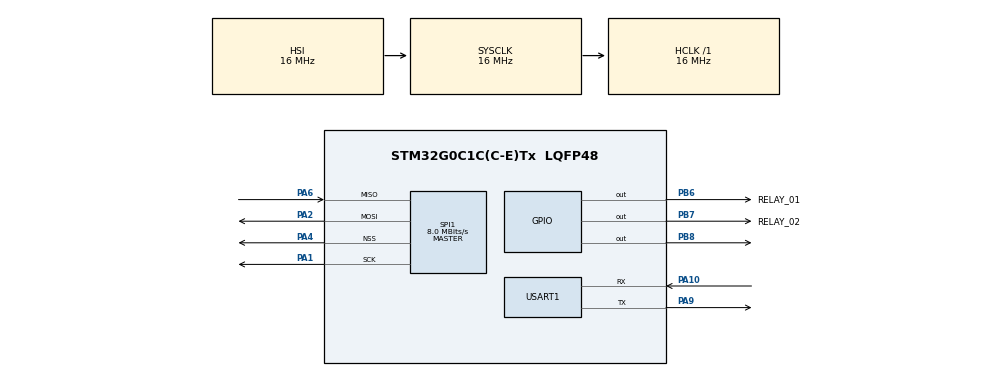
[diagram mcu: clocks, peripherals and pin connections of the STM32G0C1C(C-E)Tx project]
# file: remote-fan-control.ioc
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Mcu.Family=STM32G0
Mcu.Name=STM32G0C1C(C-E)Tx
Mcu.Package=LQFP48
PA1.Mode=Full_Duplex_Master
PA1.Signal=SPI1_SCK
PA10.Mode=Asynchronous
PA10.Signal=USART1_RX
PA2.Mode=Full_Duplex_Master
PA2.Signal=SPI1_MOSI
PA4.Mode=NSS_Signal_Hard_Output
PA4.Signal=SPI1_NSS
PA6.Mode=Full_Duplex_Master
PA6.Signal=SPI1_MISO
PA9.Mode=Asynchronous
PA9.Signal=USART1_TX
PB6.GPIO_Label=RELAY_01
PB6.Signal=GPIO_Output
PB7.GPIO_Label=RELAY_02
PB7.Signal=GPIO_Output
PB8.Signal=GPIO_Output
ProjectManager.HeapSize=0x200
ProjectManager.StackSize=0x400
ProjectManager.TargetToolchain=STM32CubeIDE
RCC.AHBFreq_Value=16000000
RCC.CortexFreq_Value=16000000
RCC.EXTERNAL_CLOCK_VALUE=48000
RCC.HCLKFreq_Value=16000000
RCC.HSE_VALUE=8000000
RCC.HSI48_VALUE=48000000
RCC.HSI_VALUE=16000000
RCC.LSE_VALUE=32768
RCC.SYSCLKFreq_VALUE=16000000
RCC.USBFreq_Value=48000000
RCC.VCOOutputFreq_Value=128000000
SPI1.CalculateBaudRate=8.0 MBits/s
SPI1.Direction=SPI_DIRECTION_2LINES
SPI1.Mode=SPI_MODE_MASTER
SPI1.VirtualNSS=VM_NSSHARD
SPI1.VirtualType=VM_MASTER
USART1.VirtualMode-Asynchronous=VM_ASYNC
VP_SYS_VS_DBSignals.Mode=DisableDeadBatterySignals
board=custom

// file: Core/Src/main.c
/* USER CODE BEGIN Header */
/**
  ******************************************************************************
  * @file           : main.c
  * @brief          : Main program body
  ******************************************************************************
  * @attention
  *
  * Copyright (c) 2026 STMicroelectronics.
  * All rights reserved.
  *
  * This software is licensed under terms that can be found in the LICENSE file
  * in the root directory of this software component.
  * If no LICENSE file comes with this software, it is provided AS-IS.
  *
  ******************************************************************************
  */
/* USER CODE END Header */
#include "main.h"

SPI_HandleTypeDef hspi1;

UART_HandleTypeDef huart1;

void SystemClock_Config(void);
static void MX_GPIO_Init(void);
static void MX_SPI1_Init(void);
static void MX_USART1_UART_Init(void);

int main(void)
{

  /* MCU Configuration--------------------------------------------------------*/

  /* Reset of all peripherals, Initializes the Flash interface and the Systick. */
  HAL_Init();

  /* Configure the system clock */
  SystemClock_Config();

  /* Initialize all configured peripherals */
  MX_GPIO_Init();
  MX_SPI1_Init();
  MX_USART1_UART_Init();
  /* USER CODE BEGIN 2 */
  char cmd[128];
  /* USER CODE END 2 */

  /* Infinite loop */
  while (1)
  {

    /* USER CODE BEGIN 3 */
    if(ble_rx(cmd, 128) == OK)
    {
      if(strstr(cmd, "TURN ON FAN"))
      {
        set_relay(RELAY_1, 1);
      }else(strstr(cmd, "TURN OFF FAN"))
      {
        set_relay(RELAY_1, 0);
      }
    }

    current_temperature = get_temp();

    if(current_temperature > 35.5f)
    {
      set_relay(RELAY_1, 1);// turn on relay (fan)
    }else if(current_temperature <= 25)
    {
      set_relay(RELAY_1, 0);// turn off relay (fan)
    }

    delay(100);
  }
  /* USER CODE END 3 */
}

void SystemClock_Config(void)
{
  RCC_OscInitTypeDef RCC_OscInitStruct = {0};
  RCC_ClkInitTypeDef RCC_ClkInitStruct = {0};

  /** Configure the main internal regulator output voltage
  */
  HAL_PWREx_ControlVoltageScaling(PWR_REGULATOR_VOLTAGE_SCALE1);

  /** Initializes the RCC Oscillators according to the specified parameters
  * in the RCC_OscInitTypeDef structure.
  */
  RCC_OscInitStruct.OscillatorType = RCC_OSCILLATORTYPE_HSI;
  RCC_OscInitStruct.HSIState = RCC_HSI_ON;
  RCC_OscInitStruct.HSIDiv = RCC_HSI_DIV1;
  RCC_OscInitStruct.HSICalibrationValue = RCC_HSICALIBRATION_DEFAULT;
  RCC_OscInitStruct.PLL.PLLState = RCC_PLL_NONE;
  if (HAL_RCC_OscConfig(&RCC_OscInitStruct) != HAL_OK)
  {
    Error_Handler();
  }

  /** Initializes the CPU, AHB and APB buses clocks
  */
  RCC_ClkInitStruct.ClockType = RCC_CLOCKTYPE_HCLK|RCC_CLOCKTYPE_SYSCLK
                              |RCC_CLOCKTYPE_PCLK1;
  RCC_ClkInitStruct.SYSCLKSource = RCC_SYSCLKSOURCE_HSI;
  RCC_ClkInitStruct.AHBCLKDivider = RCC_SYSCLK_DIV1;
  RCC_ClkInitStruct.APB1CLKDivider = RCC_HCLK_DIV1;

  if (HAL_RCC_ClockConfig(&RCC_ClkInitStruct, FLASH_LATENCY_0) != HAL_OK)
  {
    Error_Handler();
  }
}

static void MX_SPI1_Init(void)
{

  /* SPI1 parameter configuration*/
  hspi1.Instance = SPI1;
  hspi1.Init.Mode = SPI_MODE_MASTER;
  hspi1.Init.Direction = SPI_DIRECTION_2LINES;
  hspi1.Init.DataSize = SPI_DATASIZE_4BIT;
  hspi1.Init.CLKPolarity = SPI_POLARITY_LOW;
  hspi1.Init.CLKPhase = SPI_PHASE_1EDGE;
  hspi1.Init.NSS = SPI_NSS_HARD_OUTPUT;
  hspi1.Init.BaudRatePrescaler = SPI_BAUDRATEPRESCALER_2;
  hspi1.Init.FirstBit = SPI_FIRSTBIT_MSB;
  hspi1.Init.TIMode = SPI_TIMODE_DISABLE;
  hspi1.Init.CRCCalculation = SPI_CRCCALCULATION_DISABLE;
  hspi1.Init.CRCPolynomial = 7;
  hspi1.Init.CRCLength = SPI_CRC_LENGTH_DATASIZE;
  hspi1.Init.NSSPMode = SPI_NSS_PULSE_ENABLE;
  if (HAL_SPI_Init(&hspi1) != HAL_OK)
  {
    Error_Handler();
  }

}

static void MX_USART1_UART_Init(void)
{

  huart1.Instance = USART1;
  huart1.Init.BaudRate = 115200;
  huart1.Init.WordLength = UART_WORDLENGTH_8B;
  huart1.Init.StopBits = UART_STOPBITS_1;
  huart1.Init.Parity = UART_PARITY_NONE;
  huart1.Init.Mode = UART_MODE_TX_RX;
  huart1.Init.HwFlowCtl = UART_HWCONTROL_NONE;
  huart1.Init.OverSampling = UART_OVERSAMPLING_16;
  huart1.Init.OneBitSampling = UART_ONE_BIT_SAMPLE_DISABLE;
  huart1.Init.ClockPrescaler = UART_PRESCALER_DIV1;
  huart1.AdvancedInit.AdvFeatureInit = UART_ADVFEATURE_NO_INIT;
  if (HAL_UART_Init(&huart1) != HAL_OK)
  {
    Error_Handler();
  }
  if (HAL_UARTEx_SetTxFifoThreshold(&huart1, UART_TXFIFO_THRESHOLD_1_8) != HAL_OK)
  {
    Error_Handler();
  }
  if (HAL_UARTEx_SetRxFifoThreshold(&huart1, UART_RXFIFO_THRESHOLD_1_8) != HAL_OK)
  {
    Error_Handler();
  }
  if (HAL_UARTEx_DisableFifoMode(&huart1) != HAL_OK)
  {
    Error_Handler();
  }

}

static void MX_GPIO_Init(void)
{
  GPIO_InitTypeDef GPIO_InitStruct = {0};

  /* GPIO Ports Clock Enable */
  __HAL_RCC_GPIOA_CLK_ENABLE();
  __HAL_RCC_GPIOB_CLK_ENABLE();

  /*Configure GPIO pin Output Level */
  HAL_GPIO_WritePin(GPIOB, RELAY_01_Pin|RELAY_02_Pin|GPIO_PIN_8, GPIO_PIN_RESET);

  /*Configure GPIO pins : RELAY_01_Pin RELAY_02_Pin PB8 */
  GPIO_InitStruct.Pin = RELAY_01_Pin|RELAY_02_Pin|GPIO_PIN_8;
  GPIO_InitStruct.Mode = GPIO_MODE_OUTPUT_PP;
  GPIO_InitStruct.Pull = GPIO_NOPULL;
  GPIO_InitStruct.Speed = GPIO_SPEED_FREQ_LOW;
  HAL_GPIO_Init(GPIOB, &GPIO_InitStruct);

}

void Error_Handler(void)
{
  __disable_irq();
  while (1)
  {
  }
}
